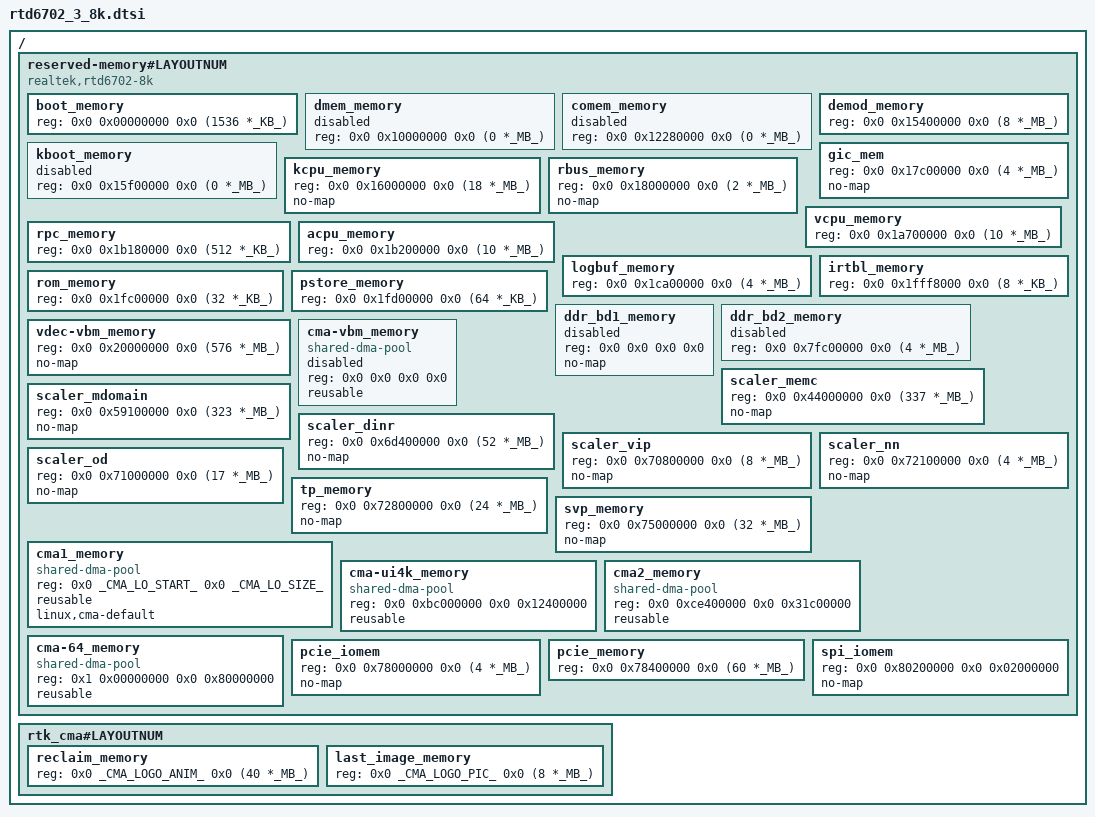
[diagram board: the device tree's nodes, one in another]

// Ref:
//  https://source.android.com/devices/architecture/dto/syntax


/ {
	reserved-memory#LAYOUTNUM {
		#address-cells = <2>;
		#size-cells = <2>;
		ranges;

		// devicetree identification board & overlay info
		compatible = "realtek,rtd6702-8k", "realtek,rtd6702";


		boot_memory {                       reg = <0x0 0x00000000 0x0 (1536 *_KB_)>;
		};

		dmem_memory {                       reg = <0x0 0x10000000 0x0 (0    *_MB_)>;
			status = "disabled";
			/* BAN_NORMAL if size */
		};

		comem_memory {                      reg = <0x0 0x12280000 0x0 (0    *_MB_)>;
			status = "disabled";
		};

		demod_memory {                      reg = <0x0 0x15400000 0x0 (8    *_MB_)>;
			/* BAN_NOT_USED */
		};

		kboot_memory {                      reg = <0x0 0x15f00000 0x0 (0    *_MB_)>;
			status = "disabled"; // it's 0 at rmm.c
		};

		kcpu_memory {                       reg = <0x0 0x16000000 0x0 (18   *_MB_)>;
			no-map;
			/* BAN_NOT_USED if ! OPTEE */
		};

		gic_mem {                           reg = <0x0 0x17c00000 0x0 (4    *_MB_)>; // HW FIXED
			no-map;
		};

		rbus_memory {                       reg = <0x0 0x18000000 0x0 (2    *_MB_)>; // HW FIXED
			no-map;
		};

		vcpu_memory {                       reg = <0x0 0x1a700000 0x0 (10   *_MB_)>;
		};

		rpc_memory {                        reg = <0x0 0x1b180000 0x0 (512  *_KB_)>;
		};

		acpu_memory {                       reg = <0x0 0x1b200000 0x0 (10   *_MB_)>;
		};

		/* The maximum reserved space for logbuf */
		logbuf_memory {                     reg = <0x0 0x1ca00000 0x0 (4    *_MB_)>;
		};

		rom_memory {                        reg = <0x0 0x1fc00000 0x0 (32   *_KB_)>;
		};

		pstore_memory {                     reg = <0x0 0x1fd00000 0x0 (64   *_KB_)>;
		};

		irtbl_memory {                      reg = <0x0 0x1fff8000 0x0 (8    *_KB_)>;
		};

		ddr_bd1_memory {                    reg = <0x0 0x0 0x0 0x0>;
			status = "disabled";
			no-map;
			/* BAN_NOT_USED if ddr_swap */
		};
		ddr_bd2_memory {                    reg = <0x0 0x7fc00000 0x0 (4    *_MB_)>;
			status = "disabled";
			/* BAN_NOT_USED if size */
		};

		// CARVEDOUT_VDEC_VBM /* 8K only */
		// (paired with ...CARVEOUT_HEAP_CHUNK_SIZE)
		/*
		 * 8K decode (chroma/luma all 60%, 13 frame 498 MB + more 2 occupied frames 38.25x2, NOT include compression header), 4MB aligned
		 */
		vdec-vbm_memory {                   reg = <0x0 0x20000000 0x0 (576  *_MB_)>;
			no-map; // VDEC_VBM(remove)

			status = "okay"; /* 8K only */
		};

		// CARVEDOUT_CMA_VBM
		// (paired with VBM_HEAP_...CHUNK_SIZE)
		cma-vbm_memory  {                   reg = <0x0 0x0 0x0 0x0>;
			/* no-map; */ // VDEC_VBM(remove), CMA_VBM(reserve)
			compatible = "shared-dma-pool"; // CMA_VBM(reserve)
			reusable;

			status = "disabled"; /* 8K only */
		};

		scaler_memc {                       reg = <0x0 0x44000000 0x0 (337  *_MB_)>;
			no-map;
		};

		scaler_mdomain {                    reg = <0x0 0x59100000 0x0 (323  *_MB_)>;
			no-map;
		};

		scaler_dinr {                       reg = <0x0 0x6d400000 0x0 (52   *_MB_)>;
			no-map;
		};

		scaler_vip {                        reg = <0x0 0x70800000 0x0 (8    *_MB_)>;
			no-map;
		};

		scaler_od {                         reg = <0x0 0x71000000 0x0 (17   *_MB_)>;
			no-map;
		};

		scaler_nn {                         reg = <0x0 0x72100000 0x0 (4    *_MB_)>;
			no-map;
		};

		tp_memory {                         reg = <0x0 0x72800000 0x0 (24   *_MB_)>;
			no-map;
		};

		// CARVEDOUT_GPU_RESERVED

		// CARVEDOUT_VDEC_RINGBUF
		svp_memory {                        reg = <0x0 0x75000000 0x0 (32   *_MB_)>;
			no-map;
		};

		// CARVEDOUT_CMA_LOW

		cma1_memory {                       reg = <0x0 _CMA_LO_START_ 0x0 _CMA_LO_SIZE_>;
			compatible = "shared-dma-pool";
			reusable;
			linux,cma-default;
		};

		// CARVEDOUT_CMA_HIGH
		// CARVEDOUT_CMA_GPU_4K
		/* [rtk_mem_layout.h]
		 * CARVEDOUT_LIMIT 0x2000 0000 (512MB)
		 * CMA_GPU_4K_SIZE 0x1240 0000
		 * [rmm.c]
		 * carvedout_buf_query[ CARVEDOUT_GPU_RESERVED ]
		 *  (DRAM_size > 0xc0000)  CMA_HIGHMEM_EXT_LARGE // 1024
		 *  (DRAM_size > 0x80000)
		 *     (DISP_8K)           CMA_HIGHMEM_LARGE     // 640
		 *    !(DISP_8K)           CMA_HIGHMEM_EXT_LARGE
		 *  (DRAM_size > 0x60000)  CMA_HIGHMEM_LARGE
		 *  (DRAM_size <= 0x60000) CMA_HIGHMEM_SMALL     // 128
		 *
		 *  tp_memory end 0x7500 0000
		 *  dram      end 0x1 8000 0000
		 *
		 *  (512M--0x74000000) + 128MB(ZRAM_RESERVED_SIZE) + 1024MB(CARVEDOUT_GPU_RESERVED)
		 *  = 0x54000000 + 0x08000000 + 0x40000000 = 0x9c00 0000
		 *
		 *  high(>512M) - carvedout - zram_reserved - gpu_reserved
		 *  (512M--0x1 8000 0000) - 0x9c00 0000 = 0x1 6000 0000 - 0x9c00 0000 = c400 0000
		 *  => cma_high 0xbc000000--0x180000000(+c4000000)
		 *  ??? NOTE: cpb (0x75000000) and pcie (0x78000000) may borrow ZRAM or GPU RESERVED ???
		 */

		/*
		 * if carvedout start < CARVEDOUT_LIMIT(512MB), then NO cma2
		 */

		/*
		 * if UI_4K, CMA_GPU_4K use an exclusive region from original CMA2
		 */
		cma-ui4k_memory {                   reg = <0x0 0xbc000000 0x0 0x12400000>; // CMA_GPU_4K_SIZE
			compatible = "shared-dma-pool";
			reusable;
		};
		cma2_memory {                       reg = <0x0 0xce400000 0x0 0x31c00000>; // CMA_HIGHMEM - CMA_GPU4K_SIZE
			compatible = "shared-dma-pool";
			reusable;
		};
		/*
		 * separate from cma2 if more than 32-bit.
		 * it's not in carvedout_buf but for kernel managed cma regions and will be mapped to rtkcma_list
		 */
		cma-64_memory {                     reg = <0x1 0x00000000 0x0 0x80000000>; // CMA_64
			compatible = "shared-dma-pool";
			reusable;
		};

		// CARVEDOUT_CMA_3
		// CARVEDOUT_CMA_LOW_LIMIT
		// CARVEDOUT_CMA_BW

		/*
		 * PCIE has different usage between Mark2 8K(4+60) and 4K(64+0)
		 */
		pcie_iomem {                        reg = <0x0 0x78000000 0x0 (4    *_MB_)>; // HW USED
			no-map;
		};
		pcie_memory {                       reg = <0x0 0x78400000 0x0 (60   *_MB_)>; // DMA
		};

		spi_iomem {                         reg = <0x0 0x80200000 0x0 0x02000000>; // HW FIXED
			no-map;
		};
	};


	rtk_cma#LAYOUTNUM {
		/*
		 * early reserve of cma1_memory
		 */

		#address-cells = <2>;
		#size-cells = <2>;

		reclaim_memory {                    reg = <0x0 _CMA_LOGO_ANIM_ 0x0 (40   *_MB_)>;
		};

		last_image_memory {                 reg = <0x0 _CMA_LOGO_PIC_  0x0 (8    *_MB_)>;
		};
	};
};



